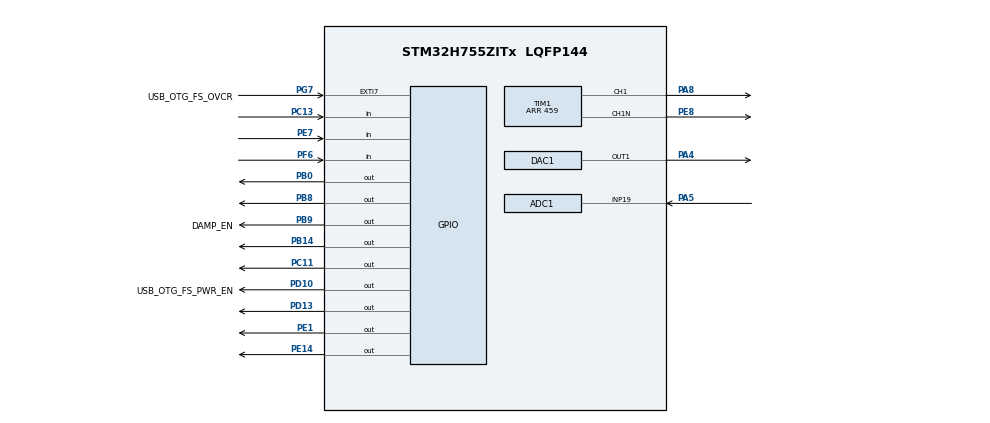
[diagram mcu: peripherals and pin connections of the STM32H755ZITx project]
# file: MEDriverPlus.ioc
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ADC1.Channel-0\#ChannelRegularConversion=ADC_CHANNEL_19
ADC1.ClockPrescaler=ADC_CLOCK_ASYNC_DIV1
ADC1.ContinuousConvMode=ENABLE
ADC1.ConversionDataManagement=ADC_CONVERSIONDATA_DMA_ONESHOT
ADC1.EOCSelection=ADC_EOC_SINGLE_CONV
ADC1.NbrOfConversionFlag=1
ADC1.OffsetNumber-0\#ChannelRegularConversion=ADC_OFFSET_NONE
ADC1.OffsetSignedSaturation-0\#ChannelRegularConversion=DISABLE
ADC1.Overrun=ADC_OVR_DATA_PRESERVED
ADC1.Rank-0\#ChannelRegularConversion=1
ADC1.Resolution=ADC_RESOLUTION_12B
ADC1.SamplingTime-0\#ChannelRegularConversion=ADC_SAMPLETIME_2CYCLES_5
ADC1.master=1
CortexM4.IPs=FATFS_M4\:I,FREERTOS_M4\:I,IWDG2\:I,RCC,WWDG2\:I,DMA,BDMA,MDMA,NVIC2\:I,USART3\:I,DEBUG,PDM2PCM_M4\:I,PWR,RESMGR_UTILITY,SYS_M4\:I,USB_DEVICE_M4\:I,USB_HOST_M4\:I,CORTEX_M4\:I,GPIO,OPENAMP_M4\:I,VREFBUF,NUCLEO-H755ZI-Q
CortexM7.IPs=FATFS_M7\:I,FREERTOS_M7\:I,IWDG1\:I,RCC\:I,WWDG1\:I,DMA\:I,BDMA\:I,MDMA\:I,NVIC1\:I,USB_OTG_FS\:I,SYS\:I,CORTEX_M7\:I,DEBUG\:I,PDM2PCM_M7\:I,PWR\:I,RESMGR_UTILITY\:I,USB_DEVICE_M7\:I,USB_HOST_M7\:I,GPIO\:I,OPENAMP_M7\:I,VREFBUF\:I,NUCLEO-H755ZI-Q\:I,TIM1\:I,USART3,ADC1\:I,DAC1\:I
CortexM7.Pins=PB9
DAC1.DAC1_OutputBuffer-DAC_OUT1=DAC_OUTPUTBUFFER_DISABLE
DAC1.DAC_Channel-DAC_OUT1=DAC_CHANNEL_1
Dma.ADC1.0.Direction=DMA_PERIPH_TO_MEMORY
Dma.ADC1.0.EventEnable=DISABLE
Dma.ADC1.0.FIFOMode=DMA_FIFOMODE_DISABLE
Dma.ADC1.0.Instance=DMA1_Stream0
Dma.ADC1.0.MemDataAlignment=DMA_MDATAALIGN_HALFWORD
Dma.ADC1.0.MemInc=DMA_MINC_ENABLE
Dma.ADC1.0.Mode=DMA_NORMAL
Dma.ADC1.0.PeriphDataAlignment=DMA_PDATAALIGN_HALFWORD
Dma.ADC1.0.PeriphInc=DMA_PINC_DISABLE
Dma.ADC1.0.Polarity=HAL_DMAMUX_REQ_GEN_RISING
Dma.ADC1.0.Priority=DMA_PRIORITY_VERY_HIGH
Dma.ADC1.0.RequestNumber=1
Dma.ADC1.0.SignalID=NONE
Dma.ADC1.0.SyncEnable=DISABLE
Dma.ADC1.0.SyncPolarity=HAL_DMAMUX_SYNC_NO_EVENT
Dma.ADC1.0.SyncRequestNumber=1
Dma.ADC1.0.SyncSignalID=NONE
Dma.Request0=ADC1
Mcu.Family=STM32H7
Mcu.Name=STM32H755ZITx
Mcu.Package=LQFP144
NUCLEO-H755ZI-Q.BUTTON=1
NUCLEO-H755ZI-Q.Bsp_Common_DEMO=true
NUCLEO-H755ZI-Q.LD1=true
NUCLEO-H755ZI-Q.LD2=true
NUCLEO-H755ZI-Q.LD3=true
NUCLEO-H755ZI-Q.VCP=true
NVIC1.ADC_IRQn=true\:0\:0\:false\:true\:true\:2\:true\:true\:true
NVIC1.DMA1_Stream0_IRQn=true\:0\:0\:false\:true\:true\:3\:false\:true\:true
NVIC1.EXTI15_10_IRQn=true\:0\:0\:false\:false\:true\:false\:true\:true
NVIC1.PriorityGroup=NVIC_PRIORITYGROUP_4
NVIC1.TIM1_UP_IRQn=true\:0\:0\:false\:true\:true\:1\:true\:true\:true
NVIC2.CM7_SEV_IRQn=true\:0\:0\:false\:true\:true\:1\:true\:false\:true
NVIC2.PriorityGroup=NVIC_PRIORITYGROUP_4
PA1.PinAttribute=CortexM7
PA1.Signal=ETH_REF_CLK
PA11.PinAttribute=CortexM7
PA11.Signal=USB_OTG_FS_DM
PA12.PinAttribute=CortexM7
PA12.Signal=USB_OTG_FS_DP
PA2.PinAttribute=CortexM7
PA2.Signal=ETH_MDIO
PA4.PinAttribute=CortexM7
PA4.Signal=COMP_DAC11_group
PA5.PinAttribute=CortexM7
PA5.Signal=ADCx_INP19
PA7.PinAttribute=CortexM7
PA7.Signal=ETH_CRS_DV
PA8.GPIO_ModeDefaultPP=GPIO_MODE_AF_PP
PA8.GPIO_PuPd=GPIO_PULLDOWN
PA8.GPIO_Speed=GPIO_SPEED_FREQ_VERY_HIGH
PA8.PinAttribute=CortexM7
PA8.Signal=S_TIM1_CH1
PA9.PinAttribute=CortexM7
PA9.Signal=USB_OTG_FS_VBUS
PB0.Signal=GPIO_Output
PB13.PinAttribute=CortexM7
PB13.Signal=ETH_TXD1
PB14.Signal=GPIO_Output
PB8.GPIO_FM8=SYSCFG_PMCR_I2C_PB8_FMP
PB8.GPIO_Speed=GPIO_SPEED_FREQ_VERY_HIGH
PB8.PinAttribute=Free
PB8.Signal=GPIO_Output
PB9.GPIO_FM9=SYSCFG_PMCR_I2C_PB9_FMP
PB9.GPIO_Label=DAMP_EN
PB9.GPIO_PuPd=GPIO_PULLDOWN
PB9.GPIO_Speed=GPIO_SPEED_FREQ_VERY_HIGH
PB9.PinAttribute=CortexM7
PB9.PinState=GPIO_PIN_SET
PB9.Signal=GPIO_Output
PC1.PinAttribute=CortexM7
PC1.Signal=ETH_MDC
PC11.GPIO_Speed=GPIO_SPEED_FREQ_VERY_HIGH
PC11.PinAttribute=Free
PC11.Signal=GPIO_Output
PC13.Signal=GPIO_Input
PC14-OSC32_IN\ (OSC32_IN).PinAttribute=Free
PC14-OSC32_IN\ (OSC32_IN).Signal=RCC_OSC32_IN
PC15-OSC32_OUT\ (OSC32_OUT).PinAttribute=Free
PC15-OSC32_OUT\ (OSC32_OUT).Signal=RCC_OSC32_OUT
PC4.PinAttribute=CortexM7
PC4.Signal=ETH_RXD0
PC5.PinAttribute=CortexM7
PC5.Signal=ETH_RXD1
PC8.PinAttribute=CortexM7
PC8.Signal=S_TIM8_CH3
PD10.GPIO_Label=USB_OTG_FS_PWR_EN
PD10.PinAttribute=Free
PD10.Signal=GPIO_Output
PD13.GPIO_Speed=GPIO_SPEED_FREQ_VERY_HIGH
PD13.PinAttribute=Free
PD13.PinState=GPIO_PIN_SET
PD13.Signal=GPIO_Output
PD8.Signal=USART3_TX
PD9.Signal=USART3_RX
PE1.Signal=GPIO_Output
PE14.GPIO_Speed=GPIO_SPEED_FREQ_VERY_HIGH
PE14.PinAttribute=Free
PE14.PinState=GPIO_PIN_SET
PE14.Signal=GPIO_Output
PE7.PinAttribute=Free
PE7.Signal=GPIO_Input
PE8.GPIO_ModeDefaultPP=GPIO_MODE_AF_PP
PE8.GPIO_PuPd=GPIO_PULLDOWN
PE8.GPIO_Speed=GPIO_SPEED_FREQ_VERY_HIGH
PE8.Mode=PWM Generation1 CH1 CH1N
PE8.PinAttribute=CortexM7
PE8.Signal=TIM1_CH1N
PF6.PinAttribute=Free
PF6.Signal=GPIO_Input
PG11.PinAttribute=CortexM7
PG11.Signal=ETH_TX_EN
PG13.PinAttribute=CortexM7
PG13.Signal=ETH_TXD0
PG7.GPIO_Label=USB_OTG_FS_OVCR
PG7.PinAttribute=Free
PG7.Signal=GPXTI7
PH0-OSC_IN\ (PH0).PinAttribute=Free
PH0-OSC_IN\ (PH0).Signal=RCC_OSC_IN
PH1-OSC_OUT\ (PH1).PinAttribute=Free
PH1-OSC_OUT\ (PH1).Signal=RCC_OSC_OUT
ProjectManager.HeapSize=M4-0x200,M7-0x200
ProjectManager.StackSize=M4-0x400,M7-0x400
ProjectManager.TargetToolchain=STM32CubeIDE
RCC.ADCFreq_Value=80000000
RCC.APB1Freq_Value=100000000
RCC.APB2Freq_Value=100000000
RCC.APB3Freq_Value=100000000
RCC.APB4Freq_Value=100000000
RCC.CortexFreq_Value=400000000
RCC.DIVM1=1
RCC.DIVM2=1
RCC.DIVN1=200
RCC.DIVN2=40
RCC.HCLKFreq_Value=100000000
RCC.HPRE=RCC_HCLK_DIV4
RCC.PLLSourceVirtual=RCC_PLLSOURCE_CSI
RCC.PWR_Regulator_Voltage_Scale=PWR_REGULATOR_VOLTAGE_SCALE1
RCC.SYSCLKFreq_VALUE=400000000
RCC.SYSCLKSource=RCC_SYSCLKSOURCE_PLLCLK
RCC.USBFreq_Value=400000000
SH.ADCx_INP19.0=ADC1_INP19,IN19-Single-Ended
SH.COMP_DAC11_group.0=DAC1_OUT1,DAC_OUT1
SH.S_TIM1_CH1.0=TIM1_CH1,PWM Generation1 CH1 CH1N
SH.S_TIM8_CH3.0=TIM8_CH3
TIM1.AutomaticOutput=TIM_AUTOMATICOUTPUT_DISABLE
TIM1.Break2State=TIM_BREAK2_DISABLE
TIM1.BreakPolarity=TIM_BREAKPOLARITY_LOW
TIM1.BreakState=TIM_BREAK_DISABLE
TIM1.Channel-PWM\ Generation1\ CH1\ CH1N=TIM_CHANNEL_1
TIM1.DeadTime=10
TIM1.OC1Preload_PWM=ENABLE
TIM1.OCFastMode_PWM-PWM\ Generation1\ CH1\ CH1N=TIM_OCFAST_ENABLE
TIM1.OffStateIDLEMode=TIM_OSSI_ENABLE
TIM1.OffStateRunMode=TIM_OSSR_ENABLE
TIM1.Period=459
TIM1.Pulse-PWM\ Generation1\ CH1\ CH1N=229
TIM1.RepetitionCounter=0
TIM1.TIM_MasterOutputTrigger=TIM_TRGO_UPDATE
TIM1.TIM_MasterSlaveMode=TIM_MASTERSLAVEMODE_DISABLE
VP_NUCLEO-H755ZI-Q_VS_BSP_COMMON.Mode=COMMON
VP_SYS_M4_VS_Systick.Mode=SysTick
VP_TIM1_VS_ClockSourceINT.Mode=Internal
board=NUCLEO-H755ZI-Q

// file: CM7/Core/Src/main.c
/* USER CODE BEGIN Header */
/**
  ******************************************************************************
  * @file           : main.c
  * @brief          : Main program body
  ******************************************************************************
  * @attention
  *
  * Copyright (c) 2024 STMicroelectronics.
  * All rights reserved.
  *
  * This software is licensed under terms that can be found in the LICENSE file
  * in the root directory of this software component.
  * If no LICENSE file comes with this software, it is provided AS-IS.
  *
  ******************************************************************************
  */
/* USER CODE END Header */
#include "main.h"
#include "adc.h"
#include "dac.h"
#include "dma.h"
#include "tim.h"
#include "gpio.h"

/* USER CODE BEGIN Includes */
#include "MEDriverPlusMain.h"
/* USER CODE END Includes */

/* USER CODE BEGIN PD */

#ifndef HSEM_ID_0
#define HSEM_ID_0 (0U) /* HW semaphore 0*/
#endif

/* USER CODE END PD */

COM_InitTypeDef BspCOMInit;
__IO uint32_t BspButtonState = BUTTON_RELEASED;

void SystemClock_Config(void);
static void MX_NVIC_Init(void);

int main(void)
{

/* USER CODE BEGIN Boot_Mode_Sequence_0 */
  int32_t timeout;
/* USER CODE END Boot_Mode_Sequence_0 */

/* USER CODE BEGIN Boot_Mode_Sequence_1 */
  /* Wait until CPU2 boots and enters in stop mode or timeout*/
//  timeout = 0xFFFF;
//  while((__HAL_RCC_GET_FLAG(RCC_FLAG_D2CKRDY) != RESET) && (timeout-- > 0));
//  if ( timeout < 0 )
//  {
//  Error_Handler();
//  }
/* USER CODE END Boot_Mode_Sequence_1 */
  /* MCU Configuration--------------------------------------------------------*/

  /* Reset of all peripherals, Initializes the Flash interface and the Systick. */
  HAL_Init();

  /* Configure the system clock */
  SystemClock_Config();
/* USER CODE BEGIN Boot_Mode_Sequence_2 */
/* When system initialization is finished, Cortex-M7 will release Cortex-M4 by means of
HSEM notification */
/*HW semaphore Clock enable*/
__HAL_RCC_HSEM_CLK_ENABLE();
/*Take HSEM */
HAL_HSEM_FastTake(HSEM_ID_0);
/*Release HSEM in order to notify the CPU2(CM4)*/
HAL_HSEM_Release(HSEM_ID_0,0);
/* wait until CPU2 wakes up from stop mode */
timeout = 0xFFFF;
while((__HAL_RCC_GET_FLAG(RCC_FLAG_D2CKRDY) == RESET) && (timeout-- > 0));
if ( timeout < 0 )
{
Error_Handler();
}
/* USER CODE END Boot_Mode_Sequence_2 */

  /* Initialize all configured peripherals */
  MX_GPIO_Init();
  MX_DMA_Init();
  MX_ADC1_Init();
  MX_TIM1_Init();
  MX_DAC1_Init();

  /* Initialize interrupts */
  MX_NVIC_Init();
  /* USER CODE BEGIN 2 */
  Setup();
  PWM_Start();
  DriverStop(-1);
  /* USER CODE END 2 */

  /* Initialize leds */
  BSP_LED_Init(LED_GREEN);
  BSP_LED_Init(LED_YELLOW);
  BSP_LED_Init(LED_RED);

  /* Initialize USER push-button, will be used to trigger an interrupt each time it's pressed.*/
  BSP_PB_Init(BUTTON_USER, BUTTON_MODE_EXTI);

  /* Initialize COM1 port (115200, 8 bits (7-bit data + 1 stop bit), no parity */
  BspCOMInit.BaudRate   = 115200;
  BspCOMInit.WordLength = COM_WORDLENGTH_8B;
  BspCOMInit.StopBits   = COM_STOPBITS_1;
  BspCOMInit.Parity     = COM_PARITY_NONE;
  BspCOMInit.HwFlowCtl  = COM_HWCONTROL_NONE;
  if (BSP_COM_Init(COM1, &BspCOMInit) != BSP_ERROR_NONE)
  {
    Error_Handler();
  }

  /* USER CODE BEGIN BSP */
  /* -- Sample board code to send message over COM1 port ---- */
  printf("Welcome to STM32 world !\n\r");
  /* -- Sample board code to switch on leds ---- */
  BSP_LED_On(LED_GREEN);
  BSP_LED_On(LED_YELLOW);
  BSP_LED_On(LED_RED);
  /* USER CODE END BSP */

  /* Infinite loop */
  /* USER CODE BEGIN WHILE */
  while (1)
  {
	  Loop();
    /* USER CODE END WHILE */

  }
}

void SystemClock_Config(void)
{
  RCC_OscInitTypeDef RCC_OscInitStruct = {0};
  RCC_ClkInitTypeDef RCC_ClkInitStruct = {0};

  /** Supply configuration update enable
  */
  HAL_PWREx_ConfigSupply(PWR_DIRECT_SMPS_SUPPLY);

  /** Configure the main internal regulator output voltage
  */
  __HAL_PWR_VOLTAGESCALING_CONFIG(PWR_REGULATOR_VOLTAGE_SCALE1);

  while(!__HAL_PWR_GET_FLAG(PWR_FLAG_VOSRDY)) {}

  /** Initializes the RCC Oscillators according to the specified parameters
  * in the RCC_OscInitTypeDef structure.
  */
  RCC_OscInitStruct.OscillatorType = RCC_OSCILLATORTYPE_CSI;
  RCC_OscInitStruct.CSIState = RCC_CSI_ON;
  RCC_OscInitStruct.CSICalibrationValue = RCC_CSICALIBRATION_DEFAULT;
  RCC_OscInitStruct.PLL.PLLState = RCC_PLL_ON;
  RCC_OscInitStruct.PLL.PLLSource = RCC_PLLSOURCE_CSI;
  RCC_OscInitStruct.PLL.PLLM = 1;
  RCC_OscInitStruct.PLL.PLLN = 200;
  RCC_OscInitStruct.PLL.PLLP = 2;
  RCC_OscInitStruct.PLL.PLLQ = 2;
  RCC_OscInitStruct.PLL.PLLR = 2;
  RCC_OscInitStruct.PLL.PLLRGE = RCC_PLL1VCIRANGE_2;
  RCC_OscInitStruct.PLL.PLLVCOSEL = RCC_PLL1VCOWIDE;
  RCC_OscInitStruct.PLL.PLLFRACN = 0;
  if (HAL_RCC_OscConfig(&RCC_OscInitStruct) != HAL_OK)
  {
    Error_Handler();
  }

  /** Initializes the CPU, AHB and APB buses clocks
  */
  RCC_ClkInitStruct.ClockType = RCC_CLOCKTYPE_HCLK|RCC_CLOCKTYPE_SYSCLK
                              |RCC_CLOCKTYPE_PCLK1|RCC_CLOCKTYPE_PCLK2
                              |RCC_CLOCKTYPE_D3PCLK1|RCC_CLOCKTYPE_D1PCLK1;
  RCC_ClkInitStruct.SYSCLKSource = RCC_SYSCLKSOURCE_PLLCLK;
  RCC_ClkInitStruct.SYSCLKDivider = RCC_SYSCLK_DIV1;
  RCC_ClkInitStruct.AHBCLKDivider = RCC_HCLK_DIV4;
  RCC_ClkInitStruct.APB3CLKDivider = RCC_APB3_DIV1;
  RCC_ClkInitStruct.APB1CLKDivider = RCC_APB1_DIV1;
  RCC_ClkInitStruct.APB2CLKDivider = RCC_APB2_DIV1;
  RCC_ClkInitStruct.APB4CLKDivider = RCC_APB4_DIV1;

  if (HAL_RCC_ClockConfig(&RCC_ClkInitStruct, FLASH_LATENCY_1) != HAL_OK)
  {
    Error_Handler();
  }
}

/**
  * @brief NVIC Configuration.
  * @retval None
  */
static void MX_NVIC_Init(void)
{
  /* TIM1_UP_IRQn interrupt configuration */
  HAL_NVIC_SetPriority(TIM1_UP_IRQn, 0, 0);
  HAL_NVIC_EnableIRQ(TIM1_UP_IRQn);
  /* ADC_IRQn interrupt configuration */
  HAL_NVIC_SetPriority(ADC_IRQn, 0, 0);
  HAL_NVIC_EnableIRQ(ADC_IRQn);
  /* DMA1_Stream0_IRQn interrupt configuration */
  HAL_NVIC_SetPriority(DMA1_Stream0_IRQn, 0, 0);
  HAL_NVIC_EnableIRQ(DMA1_Stream0_IRQn);
}

/* USER CODE BEGIN 4 */

void HAL_ADC_ConvCpltCallback(ADC_HandleTypeDef *hadc) {
  if (hadc->Instance == ADC1) {
	  __SEV();
	  BSP_LED_Toggle(LED_RED);
  }
}
/* USER CODE END 4 */

/**
  * @brief  BSP Push Button callback
  * @param  Button Specifies the pressed button
  * @retval None
  */
void BSP_PB_Callback(Button_TypeDef Button)
{
  if (Button == BUTTON_USER)
  {
    BspButtonState = BUTTON_PRESSED;
  }
}

void Error_Handler(void)
{
  __disable_irq();
  while (1)
  {
  }
}
